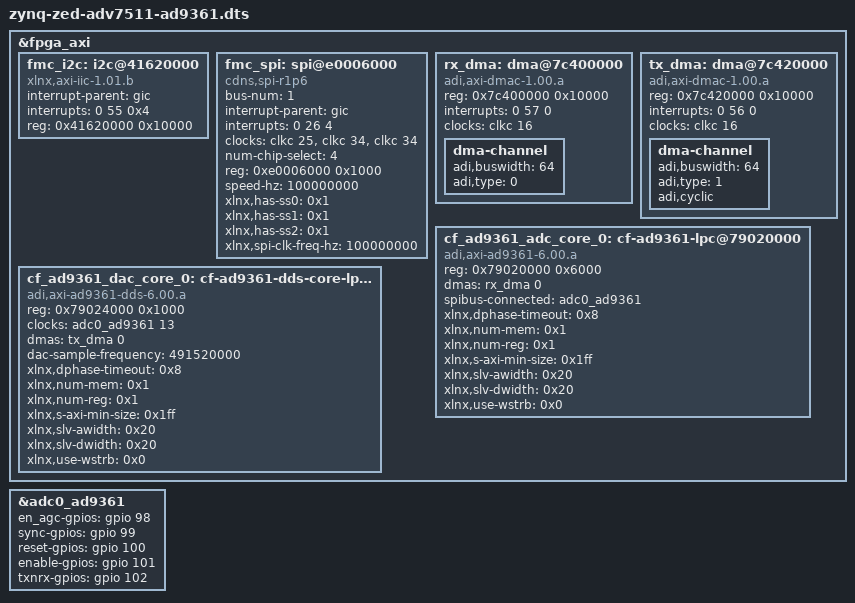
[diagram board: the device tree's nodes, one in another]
/dts-v1/;

/include/ "zynq-zed.dtsi"
/include/ "zynq-zed-adv7511.dtsi"

&fpga_axi {
	fmc_i2c: i2c@41620000 {
		compatible = "xlnx,axi-iic-1.01.b", "xlnx,xps-iic-2.00.a";
		interrupt-parent = <&gic>;
		interrupts = <0 55 0x4>;
		reg = <0x41620000 0x10000>;

		#size-cells = <0>;
		#address-cells = <1>;
	};

	fmc_spi: spi@e0006000 {
		bus-num = <1>;
		compatible = "cdns,spi-r1p6", "xlnx,zynq-spi-1.00.a", "xlnx,ps7-spi-1.00.a";
		interrupt-parent = <&gic>;
		interrupts = < 0 26 4 >;
		clock-names = "ref_clk", "aper_clk", "pclk";
		clocks = <&clkc 25>, <&clkc 34>, <&clkc 34>;
		num-chip-select = <4>;
		reg = <0xe0006000 0x1000>;
		speed-hz = <100000000>;
		xlnx,has-ss0 = <0x1>;
		xlnx,has-ss1 = <0x1>;
		xlnx,has-ss2 = <0x1>;
		xlnx,spi-clk-freq-hz = <100000000>;
		#address-cells = <1>;
		#size-cells = <0>;
	};

	rx_dma: dma@7c400000 {
		compatible = "adi,axi-dmac-1.00.a";
		reg = <0x7c400000 0x10000>;
		#dma-cells = <1>;
		interrupts = <0 57 0>;
		clocks = <&clkc 16>;

		dma-channel {
			adi,buswidth = <64>;
			adi,type = <0>;
		};
	};

	tx_dma: dma@7c420000 {
		compatible = "adi,axi-dmac-1.00.a";
		reg = <0x7c420000 0x10000>;
		#dma-cells = <1>;
		interrupts = <0 56 0>;
		clocks = <&clkc 16>;

		dma-channel {
			adi,buswidth = <64>;
			adi,type = <1>;
			adi,cyclic;
		};
	};

	cf_ad9361_adc_core_0: cf-ad9361-lpc@79020000 {
		compatible = "adi,axi-ad9361-6.00.a";
		reg = <0x79020000 0x6000>;
		dmas = <&rx_dma 0>;
		dma-names = "rx";
		spibus-connected = <&adc0_ad9361>;
		xlnx,dphase-timeout = <0x8>;
		xlnx,num-mem = <0x1>;
		xlnx,num-reg = <0x1>;
		xlnx,s-axi-min-size = <0x1ff>;
		xlnx,slv-awidth = <0x20>;
		xlnx,slv-dwidth = <0x20>;
		xlnx,use-wstrb = <0x0>;
	};

	cf_ad9361_dac_core_0: cf-ad9361-dds-core-lpc@79024000 {
		compatible = "adi,axi-ad9361-dds-6.00.a";
		reg = <0x79024000 0x1000>;
		clocks = <&adc0_ad9361 13>;
		clock-names = "sampl_clk";
		dmas = <&tx_dma 0>;
		dma-names = "tx";
		dac-sample-frequency = <491520000>;
		xlnx,dphase-timeout = <0x8>;
		xlnx,num-mem = <0x1>;
		xlnx,num-reg = <0x1>;
		xlnx,s-axi-min-size = <0x1ff>;
		xlnx,slv-awidth = <0x20>;
		xlnx,slv-dwidth = <0x20>;
		xlnx,use-wstrb = <0x0>;
	};
};

/include/ "adi-fmcomms2.dtsi"

&adc0_ad9361 {
	en_agc-gpios = <&gpio 98 0>;
	sync-gpios = <&gpio 99 0>;
	reset-gpios = <&gpio 100 0>;
	enable-gpios = <&gpio 101 0>;
	txnrx-gpios = <&gpio 102 0>;
};
